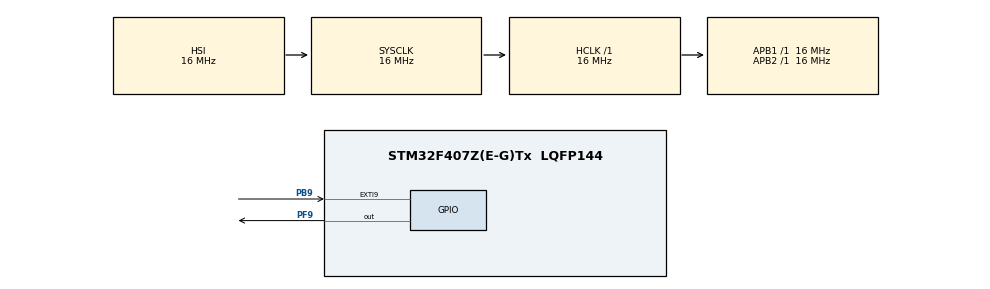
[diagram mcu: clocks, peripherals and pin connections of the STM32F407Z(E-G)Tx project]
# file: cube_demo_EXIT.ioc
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Mcu.Family=STM32F4
Mcu.Name=STM32F407Z(E-G)Tx
Mcu.Package=LQFP144
NVIC.EXTI9_5_IRQn=true\:0\:0\:false\:false\:true\:true\:true
NVIC.PriorityGroup=NVIC_PRIORITYGROUP_4
PA13.Mode=Serial_Wire
PA13.Signal=SYS_JTMS-SWDIO
PA14.Mode=Serial_Wire
PA14.Signal=SYS_JTCK-SWCLK
PB9.GPIO_PuPd=GPIO_PULLUP
PB9.Signal=GPXTI9
PF9.GPIO_PuPd=GPIO_NOPULL
PF9.Signal=GPIO_Output
PH0-OSC_IN.Mode=HSE-External-Oscillator
PH0-OSC_IN.Signal=RCC_OSC_IN
PH1-OSC_OUT.Mode=HSE-External-Oscillator
PH1-OSC_OUT.Signal=RCC_OSC_OUT
ProjectManager.HeapSize=0x200
ProjectManager.StackSize=0x400
ProjectManager.TargetToolchain=MDK-ARM V5
RCC.AHBFreq_Value=16000000
RCC.APB1Freq_Value=16000000
RCC.APB2Freq_Value=16000000
RCC.CortexFreq_Value=16000000
RCC.HSE_VALUE=25000000
RCC.HSI_VALUE=16000000
RCC.LSE_VALUE=32768
RCC.SYSCLKFreq_VALUE=16000000
RCC.VCOOutputFreq_Value=192000000
board=custom

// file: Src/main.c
/* USER CODE BEGIN Header */
/**
  ******************************************************************************
  * @file           : main.c
  * @brief          : Main program body
  ******************************************************************************
  * @attention
  *
  * <h2><center>&copy; Copyright (c) 2019 STMicroelectronics.
  * All rights reserved.</center></h2>
  *
  * This software component is licensed by ST under BSD 3-Clause license,
  * the "License"; You may not use this file except in compliance with the
  * License. You may obtain a copy of the License at:
  *                        opensource.org/licenses/BSD-3-Clause
  *
  ******************************************************************************
  */
/* USER CODE END Header */

#include "main.h"
#include "gpio.h"

void SystemClock_Config(void);

int main(void)
{

  /* MCU Configuration--------------------------------------------------------*/

  /* Reset of all peripherals, Initializes the Flash interface and the Systick. */
  HAL_Init();

  /* Configure the system clock */
  SystemClock_Config();

  /* Initialize all configured peripherals */
  MX_GPIO_Init();
  /* USER CODE BEGIN 2 */
  HAL_GPIO_WritePin(GPIOF, GPIO_PIN_9, GPIO_PIN_RESET);
  /* USER CODE END 2 */

  /* Infinite loop */
  while (1)
  {

  }
}

void SystemClock_Config(void)
{
  RCC_OscInitTypeDef RCC_OscInitStruct = {0};
  RCC_ClkInitTypeDef RCC_ClkInitStruct = {0};

  /** Configure the main internal regulator output voltage
  */
  __HAL_RCC_PWR_CLK_ENABLE();
  __HAL_PWR_VOLTAGESCALING_CONFIG(PWR_REGULATOR_VOLTAGE_SCALE1);
  /** Initializes the CPU, AHB and APB busses clocks
  */
  RCC_OscInitStruct.OscillatorType = RCC_OSCILLATORTYPE_HSI;
  RCC_OscInitStruct.HSIState = RCC_HSI_ON;
  RCC_OscInitStruct.HSICalibrationValue = RCC_HSICALIBRATION_DEFAULT;
  RCC_OscInitStruct.PLL.PLLState = RCC_PLL_NONE;
  if (HAL_RCC_OscConfig(&RCC_OscInitStruct) != HAL_OK)
  {
    Error_Handler();
  }
  /** Initializes the CPU, AHB and APB busses clocks
  */
  RCC_ClkInitStruct.ClockType = RCC_CLOCKTYPE_HCLK|RCC_CLOCKTYPE_SYSCLK
                              |RCC_CLOCKTYPE_PCLK1|RCC_CLOCKTYPE_PCLK2;
  RCC_ClkInitStruct.SYSCLKSource = RCC_SYSCLKSOURCE_HSI;
  RCC_ClkInitStruct.AHBCLKDivider = RCC_SYSCLK_DIV1;
  RCC_ClkInitStruct.APB1CLKDivider = RCC_HCLK_DIV1;
  RCC_ClkInitStruct.APB2CLKDivider = RCC_HCLK_DIV1;

  if (HAL_RCC_ClockConfig(&RCC_ClkInitStruct, FLASH_LATENCY_0) != HAL_OK)
  {
    Error_Handler();
  }
}

/* USER CODE BEGIN 4 */
void HAL_GPIO_EXTI_Callback(uint16_t GPIO_Pin)
{
  if(GPIO_Pin == GPIO_PIN_9)
  {
    /* Toggle LED1 */
    HAL_GPIO_TogglePin(GPIOF,GPIO_PIN_9);
  }
}

/* USER CODE END 4 */

void Error_Handler(void)
{
}

/************************ (C) COPYRIGHT STMicroelectronics *****END OF FILE****/
